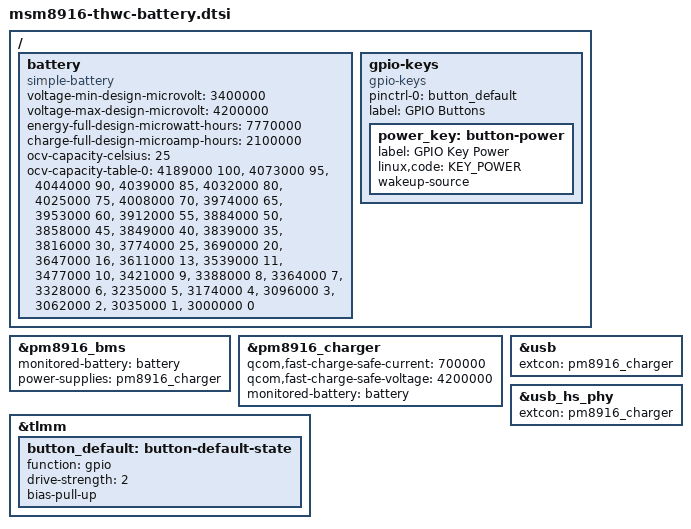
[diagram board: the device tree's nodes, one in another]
// SPDX-License-Identifier: GPL-2.0-only
// A common battery dtsi for MF32/MF601 series LTE modem dongles.

/ {
	// Limit Charge
	battery: battery {
		compatible = "simple-battery";
		voltage-min-design-microvolt = <3400000>;
		voltage-max-design-microvolt = <4200000>;
		energy-full-design-microwatt-hours = <7770000>;
		charge-full-design-microamp-hours = <2100000>;

		ocv-capacity-celsius = <25>;
		ocv-capacity-table-0 = <4189000 100>, <4073000 95>,
			<4044000 90>, <4039000 85>, <4032000 80>, <4025000 75>,
			<4008000 70>, <3974000 65>, <3953000 60>, <3912000 55>,
			<3884000 50>, <3858000 45>, <3849000 40>, <3839000 35>,
			<3816000 30>, <3774000 25>, <3690000 20>, <3647000 16>,
			<3611000 13>, <3539000 11>, <3477000 10>, <3421000 9>,
			<3388000 8>, <3364000 7>, <3328000 6>, <3235000 5>,
			<3174000 4>, <3096000 3>, <3062000 2>, <3035000 1>,
			<3000000 0>;
	};

/*
	// Full Charge
	battery: battery {
		compatible = "simple-battery";
		voltage-min-design-microvolt = <3400000>;
		voltage-max-design-microvolt = <4350000>;
		energy-full-design-microwatt-hours = <7980000>;
		charge-full-design-microamp-hours = <2100000>;

		ocv-capacity-celsius = <25>;
		ocv-capacity-table-0 = <4327000 100>, <4264000 95>,
			<4187000 90>, <4119000 85>, <4069000 80>, <4022000 75>,
			<3964000 70>, <9624000 65>, <3890000 60>, <3853000 55>,
			<3801000 50>, <3778000 45>, <3769000 40>, <3766000 35>,
			<3760000 30>, <3721000 25>, <3660000 20>, <3608000 16>,
			<3579000 13>, <3563000 11>, <3548000 10>, <3531000 9>,
			<3520000 8>, <3514000 7>, <3502000 6>, <3495000 5>,
			<3489000 4>, <3475000 3>, <3460000 2>, <3444000 1>,
			<3400000 0>;
	};
*/

	gpio-keys {
		compatible = "gpio-keys";

		pinctrl-0 = <&button_default>;
		pinctrl-names = "default";

		label = "GPIO Buttons";

		power_key: button-power {
			label = "GPIO Key Power";
			/* "gpios" are board-specific */
			linux,code = <KEY_POWER>;
			wakeup-source;
		};
	};
};

&pm8916_bms {
	monitored-battery = <&battery>;
	power-supplies = <&pm8916_charger>;

	status = "okay";
};

&pm8916_charger {
	qcom,fast-charge-safe-current = <700000>;
	qcom,fast-charge-safe-voltage = <4200000>;
	// qcom,fast-charge-safe-voltage = <4350000>;

	monitored-battery = <&battery>;

	status = "okay";
};

&usb {
	extcon = <&pm8916_charger>;
};

&usb_hs_phy {
	extcon = <&pm8916_charger>;
};

&tlmm {
	button_default: button-default-state {
		function = "gpio";
		drive-strength = <2>;
		/* "pins" are board-specific */
		bias-pull-up;
	};
};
